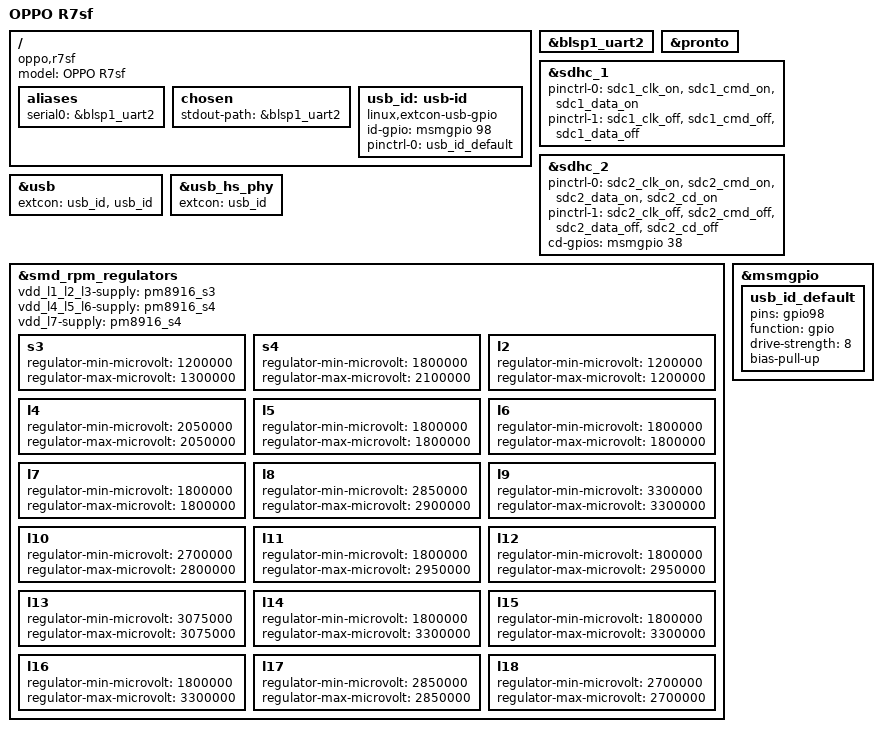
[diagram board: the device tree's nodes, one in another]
// SPDX-License-Identifier: GPL-2.0-only

/dts-v1/;

#include "msm8939-pm8916.dtsi"
#include <dt-bindings/gpio/gpio.h>

/ {
	model = "OPPO R7sf";
	compatible = "oppo,r7sf", "qcom,msm8939";

	aliases {
		serial0 = &blsp1_uart2;
	};

	chosen {
		stdout-path = &blsp1_uart2;
	};

	usb_id: usb-id {
		compatible = "linux,extcon-usb-gpio";
		id-gpio = <&msmgpio 98 GPIO_ACTIVE_HIGH>;
		pinctrl-names = "default";
		pinctrl-0 = <&usb_id_default>;
	};
};

&blsp1_uart2 {
	status = "okay";
};

&pronto {
	status = "okay";
};

&sdhc_1 {
	pinctrl-names = "default", "sleep";
	pinctrl-0 = <&sdc1_clk_on &sdc1_cmd_on &sdc1_data_on>;
	pinctrl-1 = <&sdc1_clk_off &sdc1_cmd_off &sdc1_data_off>;
	status = "okay";
};

&sdhc_2 {
	pinctrl-names = "default", "sleep";
	pinctrl-0 = <&sdc2_clk_on &sdc2_cmd_on &sdc2_data_on &sdc2_cd_on>;
	pinctrl-1 = <&sdc2_clk_off &sdc2_cmd_off &sdc2_data_off &sdc2_cd_off>;
	cd-gpios = <&msmgpio 38 GPIO_ACTIVE_HIGH>;
	status = "okay";
};

&usb {
	extcon = <&usb_id>, <&usb_id>;
	status = "okay";
};

&usb_hs_phy {
	extcon = <&usb_id>;
};

&smd_rpm_regulators {
	vdd_l1_l2_l3-supply = <&pm8916_s3>;
	vdd_l4_l5_l6-supply = <&pm8916_s4>;
	vdd_l7-supply = <&pm8916_s4>;

	s3 {
		regulator-min-microvolt = <1200000>;
		regulator-max-microvolt = <1300000>;
	};

	s4 {
		regulator-min-microvolt = <1800000>;
		regulator-max-microvolt = <2100000>;
	};

	l2 {
		regulator-min-microvolt = <1200000>;
		regulator-max-microvolt = <1200000>;
	};

	l4 {
		regulator-min-microvolt = <2050000>;
		regulator-max-microvolt = <2050000>;
	};

	l5 {
		regulator-min-microvolt = <1800000>;
		regulator-max-microvolt = <1800000>;
	};

	l6 {
		regulator-min-microvolt = <1800000>;
		regulator-max-microvolt = <1800000>;
	};

	l7 {
		regulator-min-microvolt = <1800000>;
		regulator-max-microvolt = <1800000>;
	};

	l8 {
		regulator-min-microvolt = <2850000>;
		regulator-max-microvolt = <2900000>;
	};

	l9 {
		regulator-min-microvolt = <3300000>;
		regulator-max-microvolt = <3300000>;
	};

	l10 {
		regulator-min-microvolt = <2700000>;
		regulator-max-microvolt = <2800000>;
	};

	l11 {
		regulator-min-microvolt = <1800000>;
		regulator-max-microvolt = <2950000>;
	};

	l12 {
		regulator-min-microvolt = <1800000>;
		regulator-max-microvolt = <2950000>;
	};

	l13 {
		regulator-min-microvolt = <3075000>;
		regulator-max-microvolt = <3075000>;
	};

	l14 {
		regulator-min-microvolt = <1800000>;
		regulator-max-microvolt = <3300000>;
	};

	l15 {
		regulator-min-microvolt = <1800000>;
		regulator-max-microvolt = <3300000>;
	};

	l16 {
		regulator-min-microvolt = <1800000>;
		regulator-max-microvolt = <3300000>;
	};

	l17 {
		regulator-min-microvolt = <2850000>;
		regulator-max-microvolt = <2850000>;
	};

	l18 {
		regulator-min-microvolt = <2700000>;
		regulator-max-microvolt = <2700000>;
	};
};

&msmgpio {
	usb_id_default: usb_id_default {
		pins = "gpio98";
		function = "gpio";

		drive-strength = <8>;
		bias-pull-up;
	};
};
